AUTOSAR XML (schema 4-0-3)
package /ComponentTypes
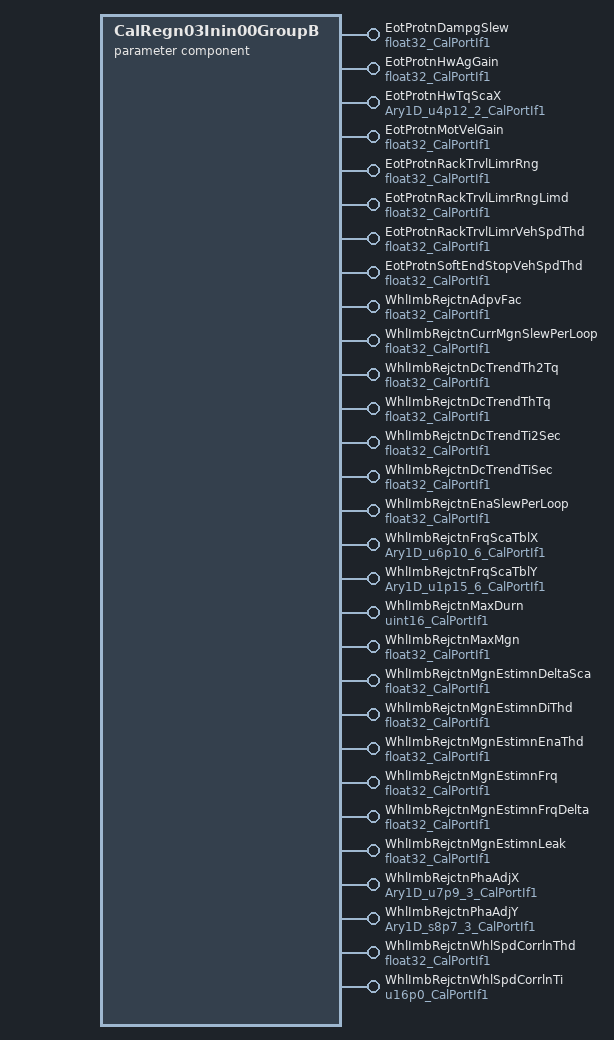
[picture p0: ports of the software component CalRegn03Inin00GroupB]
  parameter sw component type CalRegn03Inin00GroupB
    29 x provide port:
      EotProtnDampgSlew: parameter-provide-com-spec{init-value=400, parameter=Val}, provided-interface=float32_CalPortIf1
      EotProtnHwAgGain: parameter-provide-com-spec{init-value=0.15, parameter=Val}, provided-interface=float32_CalPortIf1
      EotProtnHwTqScaX: parameter-provide-com-spec{init-value=[0, 4096], parameter=Ary1D}, provided-interface=Ary1D_u4p12_2_CalPortIf1
      EotProtnMotVelGain: parameter-provide-com-spec{init-value=0.29, parameter=Val}, provided-interface=float32_CalPortIf1
      EotProtnRackTrvlLimrRng: parameter-provide-com-spec{init-value=90, parameter=Val}, provided-interface=float32_CalPortIf1
      EotProtnRackTrvlLimrRngLimd: parameter-provide-com-spec{init-value=20, parameter=Val}, provided-interface=float32_CalPortIf1
      EotProtnRackTrvlLimrVehSpdThd: parameter-provide-com-spec{init-value=20, parameter=Val}, provided-interface=float32_CalPortIf1
      EotProtnSoftEndStopVehSpdThd: parameter-provide-com-spec{init-value=30, parameter=Val}, provided-interface=float32_CalPortIf1
      WhlImbRejctnAdpvFac: parameter-provide-com-spec{init-value=0.199997, parameter=Val}, provided-interface=float32_CalPortIf1
      WhlImbRejctnCurrMgnSlewPerLoop: parameter-provide-com-spec{init-value=0.002, parameter=Val}, provided-interface=float32_CalPortIf1
      WhlImbRejctnDcTrendTh2Tq: parameter-provide-com-spec{init-value=0.1, parameter=Val}, provided-interface=float32_CalPortIf1
      WhlImbRejctnDcTrendThTq: parameter-provide-com-spec{init-value=0.05, parameter=Val}, provided-interface=float32_CalPortIf1
      WhlImbRejctnDcTrendTi2Sec: parameter-provide-com-spec{init-value=0.014, parameter=Val}, provided-interface=float32_CalPortIf1
      WhlImbRejctnDcTrendTiSec: parameter-provide-com-spec{init-value=0.125, parameter=Val}, provided-interface=float32_CalPortIf1
      WhlImbRejctnEnaSlewPerLoop: parameter-provide-com-spec{init-value=0.01, parameter=Val}, provided-interface=float32_CalPortIf1
      WhlImbRejctnFrqScaTblX: parameter-provide-com-spec{init-value=[8192, 9216, 10240, 23552, 24576, 25600], parameter=Ary1D}, provided-interface=Ary1D_u6p10_6_CalPortIf1
      WhlImbRejctnFrqScaTblY: parameter-provide-com-spec{init-value=[0, 16384, 32768, 32768, 16384, 0], parameter=Ary1D}, provided-interface=Ary1D_u1p15_6_CalPortIf1
      WhlImbRejctnMaxDurn: parameter-provide-com-spec{init-value=8000, parameter=Val}, provided-interface=uint16_CalPortIf1
      WhlImbRejctnMaxMgn: parameter-provide-com-spec{init-value=0.2, parameter=Val}, provided-interface=float32_CalPortIf1
      WhlImbRejctnMgnEstimnDeltaSca: parameter-provide-com-spec{init-value=0.0005, parameter=Val}, provided-interface=float32_CalPortIf1
      WhlImbRejctnMgnEstimnDiThd: parameter-provide-com-spec{init-value=0.209, parameter=Val}, provided-interface=float32_CalPortIf1
      WhlImbRejctnMgnEstimnEnaThd: parameter-provide-com-spec{init-value=0.21, parameter=Val}, provided-interface=float32_CalPortIf1
      WhlImbRejctnMgnEstimnFrq: parameter-provide-com-spec{init-value=14, parameter=Val}, provided-interface=float32_CalPortIf1
      WhlImbRejctnMgnEstimnFrqDelta: parameter-provide-com-spec{init-value=4, parameter=Val}, provided-interface=float32_CalPortIf1
      WhlImbRejctnMgnEstimnLeak: parameter-provide-com-spec{init-value=1, parameter=Val}, provided-interface=float32_CalPortIf1
      WhlImbRejctnPhaAdjX: parameter-provide-com-spec{init-value=[5120, 10240, 15360], parameter=Ary1D}, provided-interface=Ary1D_u7p9_3_CalPortIf1
      WhlImbRejctnPhaAdjY: parameter-provide-com-spec{init-value=[17280, 15360, 15360], parameter=Ary1D}, provided-interface=Ary1D_s8p7_3_CalPortIf1
      WhlImbRejctnWhlSpdCorrlnThd: parameter-provide-com-spec{init-value=90, parameter=Val}, provided-interface=float32_CalPortIf1
      WhlImbRejctnWhlSpdCorrlnTi: parameter-provide-com-spec{init-value=500, parameter=Val}, provided-interface=u16p0_CalPortIf1
